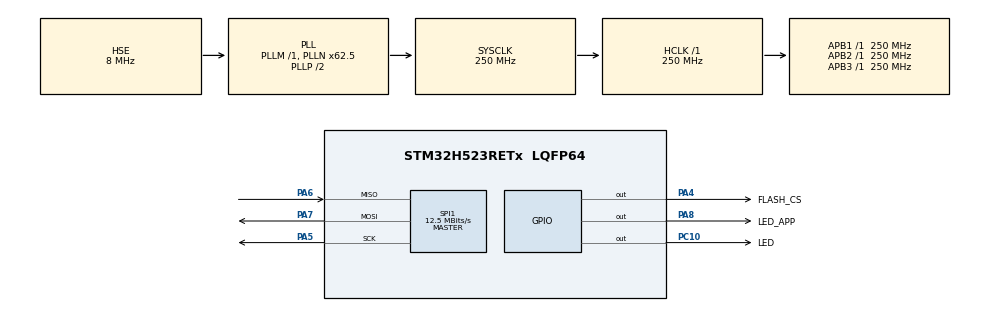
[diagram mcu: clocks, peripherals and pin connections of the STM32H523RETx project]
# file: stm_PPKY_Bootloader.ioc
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BOOTPATH.BootPathName=LEGACY
BOOTPATH.UserSelectedBootPath=LEGACY
CORTEX_M33_NS.AccessPermission-Cortex_Memory_Protection_Unit_Region0_Settings=MPU_REGION_ALL_RO
CORTEX_M33_NS.Attributes0=MPU_ATTRIBUTES_NUMBER0
CORTEX_M33_NS.AttributesIndex-Cortex_Memory_Protection_Unit_Region0_Settings=MPU_ATTRIBUTES_NUMBER0
CORTEX_M33_NS.BaseAddress-Cortex_Memory_Protection_Unit_Region0_Settings=0x08FFF800
CORTEX_M33_NS.Enable-Cortex_Memory_Protection_Unit_Region0_Settings=MPU_REGION_ENABLE
CORTEX_M33_NS.LimitAddress-Cortex_Memory_Protection_Unit_Region0_Settings=0x08FFFFFF
CORTEX_M33_NS.MPU_Control=MPU_PRIVILEGED_DEFAULT
CORTEX_M33_NS.Memorytype0=MPU_DEVICE
CORTEX_M33_NS.userName=CORTEX_M33
FLASH.OB_User_Configuration_active=false
Mcu.Family=STM32H5
Mcu.Name=STM32H523RETx
Mcu.Package=LQFP64
NVIC.PriorityGroup=NVIC_PRIORITYGROUP_4
PA13(JTMS/SWDIO).Signal=DEBUG_JTMS-SWDIO
PA14(JTCK/SWCLK).Signal=DEBUG_JTCK-SWCLK
PA4.GPIO_Label=FLASH_CS
PA4.GPIO_PuPd=GPIO_PULLUP
PA4.GPIO_Speed=GPIO_SPEED_FREQ_VERY_HIGH
PA4.PinAttribute=Free
PA4.PinState=GPIO_PIN_SET
PA4.Signal=GPIO_Output
PA5.GPIO_PuPd=GPIO_NOPULL
PA5.GPIO_Speed=GPIO_SPEED_FREQ_VERY_HIGH
PA5.Mode=Full_Duplex_Master
PA5.PinAttribute=Free
PA5.Signal=SPI1_SCK
PA6.GPIO_PuPd=GPIO_NOPULL
PA6.GPIO_Speed=GPIO_SPEED_FREQ_VERY_HIGH
PA6.Mode=Full_Duplex_Master
PA6.PinAttribute=Free
PA6.Signal=SPI1_MISO
PA7.GPIO_Speed=GPIO_SPEED_FREQ_VERY_HIGH
PA7.Mode=Full_Duplex_Master
PA7.PinAttribute=Free
PA7.Signal=SPI1_MOSI
PA8.GPIO_Label=LED_APP
PA8.Signal=GPIO_Output
PC10.GPIO_Label=LED
PC10.Signal=GPIO_Output
PC14-OSC32_IN(OSC32_IN).Mode=LSE-External-Oscillator
PC14-OSC32_IN(OSC32_IN).Signal=RCC_OSC32_IN
PC15-OSC32_OUT(OSC32_OUT).Mode=LSE-External-Oscillator
PC15-OSC32_OUT(OSC32_OUT).Signal=RCC_OSC32_OUT
PH0-OSC_IN(PH0).Mode=HSE-External-Oscillator
PH0-OSC_IN(PH0).Signal=RCC_OSC_IN
PH1-OSC_OUT(PH1).Mode=HSE-External-Oscillator
PH1-OSC_OUT(PH1).Signal=RCC_OSC_OUT
ProjectManager.HeapSize=0x200
ProjectManager.StackSize=0x400
ProjectManager.TargetToolchain=STM32CubeIDE
RCC.ADCCLockSelection=RCC_ADCDACCLKSOURCE_HSE
RCC.ADCFreq_Value=8000000
RCC.AHBFreq_Value=250000000
RCC.APB1Freq_Value=250000000
RCC.APB1TimFreq_Value=250000000
RCC.APB2Freq_Value=250000000
RCC.APB2TimFreq_Value=250000000
RCC.APB3Freq_Value=250000000
RCC.CSI_VALUE=4000000
RCC.CortexFreq_Value=250000000
RCC.EPOD_VALUE=8000000
RCC.HCLKFreq_Value=250000000
RCC.HSE_VALUE=8000000
RCC.HSI48_VALUE=48000000
RCC.HSI_VALUE=64000000
RCC.I2C1CLockSelection=RCC_I2C1CLKSOURCE_HSI
RCC.LSIRC_VALUE=32000
RCC.PLL1Q=5
RCC.PLL2M=2
RCC.PLL2Source=RCC_PLL2_SOURCE_HSE
RCC.PLL3N=16
RCC.PLL3P=1
RCC.PLL3Source=RCC_PLL3_SOURCE_HSE
RCC.PLLFRACN=4096
RCC.PLLN=62
RCC.PLLSourceVirtual=RCC_PLL1_SOURCE_HSE
RCC.RTCClockSelection=RCC_RTCCLKSOURCE_LSE
RCC.SYSCLKFreq_VALUE=250000000
RCC.SYSCLKSource=RCC_SYSCLKSOURCE_PLLCLK
RCC.USBFreq_Value=48000000
RCC.VCOOutputFreq_Value=500000000
SPI1.BaudRatePrescaler=SPI_BAUDRATEPRESCALER_8
SPI1.CalculateBaudRate=12.5 MBits/s
SPI1.DataSize=SPI_DATASIZE_8BIT
SPI1.Direction=SPI_DIRECTION_2LINES
SPI1.MasterKeepIOState=SPI_MASTER_KEEP_IO_STATE_DISABLE
SPI1.Mode=SPI_MODE_MASTER
SPI1.VirtualType=VM_MASTER
STMicroelectronics.X-CUBE-TOUCHGFX.4.25.0.tgfx_custom_height=64
STMicroelectronics.X-CUBE-TOUCHGFX.4.25.0.tgfx_custom_width=128
STMicroelectronics.X-CUBE-TOUCHGFX.4.25.0.tgfx_pixel_format=BW\:1
STMicroelectronics.X-CUBE-TOUCHGFX.4.25.0_IsPackSelfContextualization=true
VP_BOOTPATH_VS_BOOTPATH.Mode=BP_Activate
VP_CORTEX_M33_NS_VS_Ext.Mode=External_Mode
VP_FLASH_SIG_Activate_FlashIP.Mode=Activate_FlashIP
VP_ICACHE_VS_ICACHE.Mode=DirectMappedCache
VP_MEMORYMAP_VS_MEMORYMAP.Mode=CurAppReg
VP_PWR_VS_DBSignals.Mode=DisableDeadBatterySignals
VP_PWR_VS_LPOM.Mode=PowerOptimisation
VP_PWR_VS_SECSignals.Mode=Security/Privilege
board=custom

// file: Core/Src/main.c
/* USER CODE BEGIN Header */
/**
  ******************************************************************************
  * @file           : main.c
  * @brief          : Main program body
  ******************************************************************************
  * @attention
  *
  * Copyright (c) 2026 STMicroelectronics.
  * All rights reserved.
  *
  * This software is licensed under terms that can be found in the LICENSE file
  * in the root directory of this software component.
  * If no LICENSE file comes with this software, it is provided AS-IS.
  *
  ******************************************************************************
  */
/* USER CODE END Header */
#include "main.h"

/* USER CODE BEGIN Includes */
#include "spif.h"
#include "boot.h"
/* USER CODE END Includes */

SPI_HandleTypeDef hspi1;

/* USER CODE BEGIN PV */
SPIF_HandleTypeDef hFlash;
/* USER CODE END PV */

void SystemClock_Config(void);
static void MPU_Config(void);
static void MX_GPIO_Init(void);
static void MX_SPI1_Init(void);
static void MX_FLASH_Init(void);
static void MX_ICACHE_Init(void);

int main(void)
{

  /* MCU Configuration--------------------------------------------------------*/

  /* MPU Configuration--------------------------------------------------------*/
  MPU_Config();

  /* Reset of all peripherals, Initializes the Flash interface and the Systick. */
  HAL_Init();

  /* Configure the system clock */
  SystemClock_Config();

  /* Initialize all configured peripherals */
  MX_GPIO_Init();
  MX_SPI1_Init();
  MX_FLASH_Init();
  MX_ICACHE_Init();
  /* USER CODE BEGIN 2 */
  HAL_GPIO_WritePin(FLASH_CS_GPIO_Port, FLASH_CS_Pin, GPIO_PIN_SET);
  (void)SPIF_Init(&hFlash, &hspi1, FLASH_CS_GPIO_Port, FLASH_CS_Pin);
  BootProcess();
  /* USER CODE END 2 */

  /* Infinite loop */
  while (1)
  {

  }
}

void SystemClock_Config(void)
{
  RCC_OscInitTypeDef RCC_OscInitStruct = {0};
  RCC_ClkInitTypeDef RCC_ClkInitStruct = {0};

  /** Configure the main internal regulator output voltage
  */
  __HAL_PWR_VOLTAGESCALING_CONFIG(PWR_REGULATOR_VOLTAGE_SCALE0);

  while(!__HAL_PWR_GET_FLAG(PWR_FLAG_VOSRDY)) {}

  /** Initializes the RCC Oscillators according to the specified parameters
  * in the RCC_OscInitTypeDef structure.
  */
  RCC_OscInitStruct.OscillatorType = RCC_OSCILLATORTYPE_HSE;
  RCC_OscInitStruct.HSEState = RCC_HSE_ON;
  RCC_OscInitStruct.PLL.PLLState = RCC_PLL_ON;
  RCC_OscInitStruct.PLL.PLLSource = RCC_PLL1_SOURCE_HSE;
  RCC_OscInitStruct.PLL.PLLM = 1;
  RCC_OscInitStruct.PLL.PLLN = 62;
  RCC_OscInitStruct.PLL.PLLP = 2;
  RCC_OscInitStruct.PLL.PLLQ = 5;
  RCC_OscInitStruct.PLL.PLLR = 2;
  RCC_OscInitStruct.PLL.PLLRGE = RCC_PLL1_VCIRANGE_3;
  RCC_OscInitStruct.PLL.PLLVCOSEL = RCC_PLL1_VCORANGE_WIDE;
  RCC_OscInitStruct.PLL.PLLFRACN = 4096;
  if (HAL_RCC_OscConfig(&RCC_OscInitStruct) != HAL_OK)
  {
    Error_Handler();
  }

  /** Initializes the CPU, AHB and APB buses clocks
  */
  RCC_ClkInitStruct.ClockType = RCC_CLOCKTYPE_HCLK|RCC_CLOCKTYPE_SYSCLK
                              |RCC_CLOCKTYPE_PCLK1|RCC_CLOCKTYPE_PCLK2
                              |RCC_CLOCKTYPE_PCLK3;
  RCC_ClkInitStruct.SYSCLKSource = RCC_SYSCLKSOURCE_PLLCLK;
  RCC_ClkInitStruct.AHBCLKDivider = RCC_SYSCLK_DIV1;
  RCC_ClkInitStruct.APB1CLKDivider = RCC_HCLK_DIV1;
  RCC_ClkInitStruct.APB2CLKDivider = RCC_HCLK_DIV1;
  RCC_ClkInitStruct.APB3CLKDivider = RCC_HCLK_DIV1;

  if (HAL_RCC_ClockConfig(&RCC_ClkInitStruct, FLASH_LATENCY_5) != HAL_OK)
  {
    Error_Handler();
  }

   /* Select SysTick source clock */
  HAL_SYSTICK_CLKSourceConfig(SYSTICK_CLKSOURCE_HCLK);

   /* Re-Initialize Tick with new clock source */
  if (HAL_InitTick(TICK_INT_PRIORITY) != HAL_OK)
  {
    Error_Handler();
  }

  /** Configure the programming delay
  */
  __HAL_FLASH_SET_PROGRAM_DELAY(FLASH_PROGRAMMING_DELAY_2);
}

static void MX_FLASH_Init(void)
{

  if (HAL_FLASH_Unlock() != HAL_OK)
  {
    Error_Handler();
  }
  if (HAL_FLASH_Lock() != HAL_OK)
  {
    Error_Handler();
  }

}

static void MX_ICACHE_Init(void)
{

  /** Enable instruction cache in 1-way (direct mapped cache)
  */
  if (HAL_ICACHE_ConfigAssociativityMode(ICACHE_1WAY) != HAL_OK)
  {
    Error_Handler();
  }
  if (HAL_ICACHE_Enable() != HAL_OK)
  {
    Error_Handler();
  }

}

static void MX_SPI1_Init(void)
{

  /* SPI1 parameter configuration*/
  hspi1.Instance = SPI1;
  hspi1.Init.Mode = SPI_MODE_MASTER;
  hspi1.Init.Direction = SPI_DIRECTION_2LINES;
  hspi1.Init.DataSize = SPI_DATASIZE_8BIT;
  hspi1.Init.CLKPolarity = SPI_POLARITY_LOW;
  hspi1.Init.CLKPhase = SPI_PHASE_1EDGE;
  hspi1.Init.NSS = SPI_NSS_SOFT;
  hspi1.Init.BaudRatePrescaler = SPI_BAUDRATEPRESCALER_8;
  hspi1.Init.FirstBit = SPI_FIRSTBIT_MSB;
  hspi1.Init.TIMode = SPI_TIMODE_DISABLE;
  hspi1.Init.CRCCalculation = SPI_CRCCALCULATION_DISABLE;
  hspi1.Init.CRCPolynomial = 0x7;
  hspi1.Init.NSSPMode = SPI_NSS_PULSE_ENABLE;
  hspi1.Init.NSSPolarity = SPI_NSS_POLARITY_LOW;
  hspi1.Init.FifoThreshold = SPI_FIFO_THRESHOLD_01DATA;
  hspi1.Init.MasterSSIdleness = SPI_MASTER_SS_IDLENESS_00CYCLE;
  hspi1.Init.MasterInterDataIdleness = SPI_MASTER_INTERDATA_IDLENESS_00CYCLE;
  hspi1.Init.MasterReceiverAutoSusp = SPI_MASTER_RX_AUTOSUSP_DISABLE;
  hspi1.Init.MasterKeepIOState = SPI_MASTER_KEEP_IO_STATE_DISABLE;
  hspi1.Init.IOSwap = SPI_IO_SWAP_DISABLE;
  hspi1.Init.ReadyMasterManagement = SPI_RDY_MASTER_MANAGEMENT_INTERNALLY;
  hspi1.Init.ReadyPolarity = SPI_RDY_POLARITY_HIGH;
  if (HAL_SPI_Init(&hspi1) != HAL_OK)
  {
    Error_Handler();
  }

}

static void MX_GPIO_Init(void)
{
  GPIO_InitTypeDef GPIO_InitStruct = {0};

  /* GPIO Ports Clock Enable */
  __HAL_RCC_GPIOC_CLK_ENABLE();
  __HAL_RCC_GPIOH_CLK_ENABLE();
  __HAL_RCC_GPIOA_CLK_ENABLE();

  /*Configure GPIO pin Output Level */
  HAL_GPIO_WritePin(FLASH_CS_GPIO_Port, FLASH_CS_Pin, GPIO_PIN_SET);

  /*Configure GPIO pin Output Level */
  HAL_GPIO_WritePin(LED_GPIO_Port, LED_Pin, GPIO_PIN_RESET);
  HAL_GPIO_WritePin(LED_APP_GPIO_Port, LED_APP_Pin, GPIO_PIN_RESET);

  /*Configure GPIO pin : FLASH_CS_Pin */
  GPIO_InitStruct.Pin = FLASH_CS_Pin;
  GPIO_InitStruct.Mode = GPIO_MODE_OUTPUT_PP;
  GPIO_InitStruct.Pull = GPIO_PULLUP;
  GPIO_InitStruct.Speed = GPIO_SPEED_FREQ_VERY_HIGH;
  HAL_GPIO_Init(FLASH_CS_GPIO_Port, &GPIO_InitStruct);

  /*Configure GPIO pin : LED_Pin */
  GPIO_InitStruct.Pin = LED_Pin;
  GPIO_InitStruct.Mode = GPIO_MODE_OUTPUT_PP;
  GPIO_InitStruct.Pull = GPIO_NOPULL;
  GPIO_InitStruct.Speed = GPIO_SPEED_FREQ_LOW;
  HAL_GPIO_Init(LED_GPIO_Port, &GPIO_InitStruct);

  /*Configure GPIO pin : LED_APP_Pin (PA8 on PPKY v1) */
  GPIO_InitStruct.Pin = LED_APP_Pin;
  GPIO_InitStruct.Mode = GPIO_MODE_OUTPUT_PP;
  GPIO_InitStruct.Pull = GPIO_NOPULL;
  GPIO_InitStruct.Speed = GPIO_SPEED_FREQ_LOW;
  HAL_GPIO_Init(LED_APP_GPIO_Port, &GPIO_InitStruct);

}

 /* MPU Configuration */

void MPU_Config(void)
{
  MPU_Region_InitTypeDef MPU_InitStruct = {0};
  MPU_Attributes_InitTypeDef MPU_AttributesInit = {0};

  /* Disables the MPU */
  HAL_MPU_Disable();

  /** Initializes and configures the Region 0 and the memory to be protected
  */
  MPU_InitStruct.Enable = MPU_REGION_ENABLE;
  MPU_InitStruct.Number = MPU_REGION_NUMBER0;
  MPU_InitStruct.BaseAddress = 0x08FFF800;
  MPU_InitStruct.LimitAddress = 0x08FFFFFF;
  MPU_InitStruct.AttributesIndex = MPU_ATTRIBUTES_NUMBER0;
  MPU_InitStruct.AccessPermission = MPU_REGION_ALL_RO;
  MPU_InitStruct.DisableExec = MPU_INSTRUCTION_ACCESS_ENABLE;
  MPU_InitStruct.IsShareable = MPU_ACCESS_NOT_SHAREABLE;

  HAL_MPU_ConfigRegion(&MPU_InitStruct);

  /** Initializes and configures the Attribute 0 and the memory to be protected
  */
  MPU_AttributesInit.Number = MPU_ATTRIBUTES_NUMBER0;
  MPU_AttributesInit.Attributes = MPU_DEVICE_nGnRnE;

  HAL_MPU_ConfigMemoryAttributes(&MPU_AttributesInit);
  /* Enables the MPU */
  HAL_MPU_Enable(MPU_PRIVILEGED_DEFAULT);

}

void Error_Handler(void)
{
  __disable_irq();
  while (1)
  {
  }
}
